# MIK32 register map
Vendor: Mikron; Series: MIK32; File version: 1.0
Registers are 32-bit, read-write, reset 0x0 unless marked. A register's access mark holds for its fields unless they carry their own. Offsets are from the block's base; [hi:lo] are bit positions; {n}, {i} and the like mark numbered series; 'fields as' and 'values as' point back to an identical list.

## PAD_CONFIG — Модуль управления функцией ввода/вывода
Base 0x00050C00
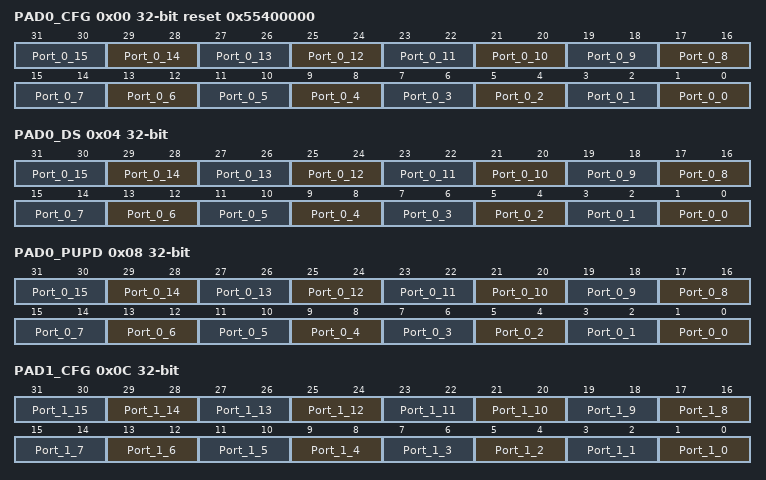
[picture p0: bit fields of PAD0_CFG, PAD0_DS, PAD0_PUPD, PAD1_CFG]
0x00 PAD0_CFG reset 0x55400000 — Управление функциями выводов PORT0
  [all] fields
    0=Func1_GPIO (Первая функция (порт общего назначения)); 1=Func2_interface (Вторая функция (последовательный интерфейс)); 2=Func3_interface_or_timer (Третья функция (последовательный интерфейс или таймер)); 3=Func4_Analog (Четвертая функция (аналоговый сигнал))
  [2n+1:2n] Port_0_{n} (n=0..15) — Значения двух бит кодируют выбранный функционал для вывода
0x04 PAD0_DS — Управление нагрузочной способностью выводов PORT0
  [all] fields
    0=2mA (Нагрузочная способность вывода 2мА); 1=4mA (Нагрузочная способность вывода 4мА); 0b1x=8mA (Нагрузочная способность вывода 8мА)
  [2n+1:2n] Port_0_{n} (n=0..15) — Значения двух бит кодируют выбранный режим для вывода
0x08 PAD0_PUPD — Управление резисторами подтяжки выводов PORT0
  [all] fields
    0=Pull_none (Без подтяжки); 1=Pull_up (Подтяжка к питанию); 2=Pull_down (Подтяжка к земле)
  [2n+1:2n] Port_0_{n} (n=0..15) — Значения двух бит кодируют выбранный режим для вывода
0x0C PAD1_CFG — Управление функциями выводов PORT1
  [all] fields
    values as the fields of PAD0_CFG
  [2n+1:2n] Port_1_{n} (n=0..15) — Значения двух бит кодируют выбранный функционал для вывода
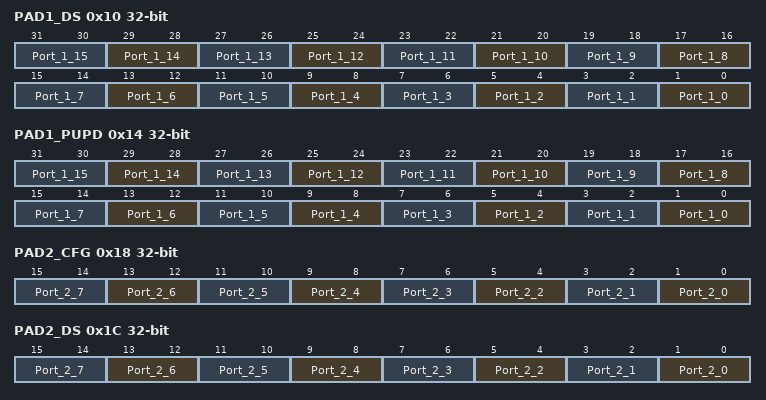
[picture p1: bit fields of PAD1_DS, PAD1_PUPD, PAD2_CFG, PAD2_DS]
0x10 PAD1_DS — Управление нагрузочной способностью выводов PORT1
  [all] fields
    values as the fields of PAD0_DS
  [2n+1:2n] Port_1_{n} (n=0..15) — Значения двух бит кодируют выбранный режим для вывода
0x14 PAD1_PUPD — Управление резисторами подтяжки выводов PORT1
  [all] fields
    values as the fields of PAD0_PUPD
  [2n+1:2n] Port_1_{n} (n=0..15) — Значения двух бит кодируют выбранный режим для вывода
0x18 PAD2_CFG — Управление функциями выводов PORT2
  [all] fields
    values as the fields of PAD0_CFG
  [2n+1:2n] Port_2_{n} (n=0..7) — Значения двух бит кодируют выбранный функционал для вывода
0x1C PAD2_DS — Управление нагрузочной способностью выводов PORT2
  [all] fields
    values as the fields of PAD0_DS
  [2n+1:2n] Port_2_{n} (n=0..7) — Значения двух бит кодируют выбранный режим для вывода
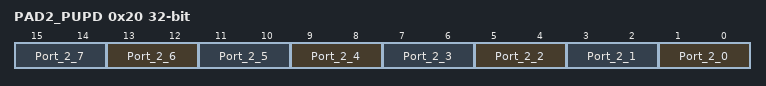
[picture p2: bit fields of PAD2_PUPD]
0x20 PAD2_PUPD — Управление резисторами подтяжки выводов PORT2
  [all] fields
    values as the fields of PAD0_PUPD
  [2n+1:2n] Port_2_{n} (n=0..7) — Значения двух бит кодируют выбранный режим для вывода

## WDT_BUS — Сторожевой таймер шины
Base 0x00051000
0x00 TIMEOUT — Определеяет количество циклов ожидания до формирования ошибки. Значения от 0 до 15. Количество циклов ожидания вычисляется как 2^TIMEOUT.
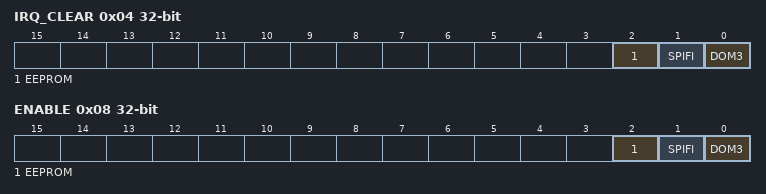
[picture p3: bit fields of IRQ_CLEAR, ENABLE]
0x04 IRQ_CLEAR wo write-1-clears — Сброс прерываний
  [2] EEPROM write-1-clears — Сброс прерываний для монитора шины EEPROM
  [1] SPIFI write-1-clears — Сброс прерываний для монитора шины SPIFI
  [0] DOM3 write-1-clears — Сброс прерываний для монитора шины периферийных устройств
0x08 ENABLE — Запуск/отключение мониторов шины
  [all] fields
    0=Disable (Монитор шины выключен); 1=Enable (Монитор шины включен)
  [2] EEPROM — Управление монитором шины EEPROM
  [1] SPIFI — Управление монитором шины SPIFI
  [0] DOM3 — Управление монитором шины периферийных устройств

## BOOT_MANAGER — Блок управления режимом загрузки
Base 0x00060800
0x00 BOOT — Регистр режима загрузки
  [1:0] BOOT_MODE — Регистр режима загрузки. При чтении, возвращает режим, который будет использоваться для следующего сброса системного домена. При записи – установка нового режима загрузки.
    0=EEPROM (Старт из встроенной памяти EEPROM); 1=RAM (Старт из системного ОЗУ); 2=SPIFI (Старт из внешней памяти с использованием контроллера SPIFI)

## CRYPTO — Крипто-блок
Base 0x00080000
0x00 BLOCK — Буфер данных для шифрования
0x04 KEY wo — Буфер данных ключа
0x08 INIT wo — Буфер данных вектора инициализации
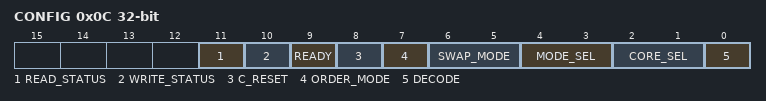
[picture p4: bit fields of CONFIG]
0x0C CONFIG — Регистр конфигурации
  [11] READ_STATUS ro — Буфер данных доступен для чтения
    0=Unavailable (Недоступно); 1=Available (Доступно)
  [10] WRITE_STATUS ro — Буфер данных доступен для записи
    0=Unavailable (Недоступно); 1=Available (Доступно)
  [9] READY ro — Состояние доступности модуля
    0=Busy (Занято); 1=Available (Доступно)
  [8] C_RESET — Сброс счётчиков загружаемых/выгружаемых данных
  [7] ORDER_MODE — Выбор порядка загрузки/выгрузки
    0=LSW (От младшего слова к старшему); 1=MSW (От старшего слова к младшему)
  [6:5] SWAP_MODE — Регистр выбора режима перестановки слова
    0=None (Нет перестановки); 1=Half_word (Перестановка по полуслову); 2=Byte (Перестановки по байтам); 3=Bit (Перестановка по битам)
  [4:3] MODE_SEL — Регистр выбора режима шифрования
    0=ECB (Режиме простой замены (ECB)); 1=CBC (Режим сцепления блоков (CBC)); 2=CTR (Режим гаммирования (CTR))
  [2:1] CORE_SEL — Регистр выбора алгоритма шифрования
    0=Kuznechik («Кузнечик»); 1=Magma («Магма»); 2=AES
  [0] DECODE — Задаёт режим хода вычислительного ядра
    0=Encode (Прямой ход (шифрование)); 1=Decode (Обратный ход (расшифровка))
